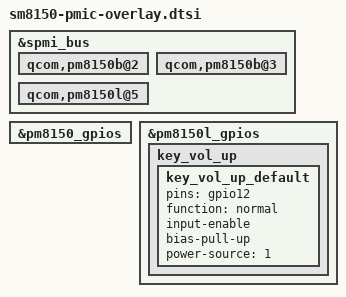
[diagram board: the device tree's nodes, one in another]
/*
 * Copyright (c) 2017-2018, The Linux Foundation. All rights reserved.
 *
 * This program is free software; you can redistribute it and/or modify
 * it under the terms of the GNU General Public License version 2 and
 * only version 2 as published by the Free Software Foundation.
 *
 * This program is distributed in the hope that it will be useful,
 * but WITHOUT ANY WARRANTY; without even the implied warranty of
 * MERCHANTABILITY or FITNESS FOR A PARTICULAR PURPOSE.  See the
 * GNU General Public License for more details.
 */

#include "pm8150.dtsi"
#include "pm8150l.dtsi"
#include <dt-bindings/pinctrl/qcom,pmic-gpio.h>

&spmi_bus {
	qcom,pm8150b@2 {
		/delete-node/qcom,usb-pdphy@1700;
		/delete-node/qcom,temp-alarm@2400;
	};
	qcom,pm8150b@3 {
		/delete-node/qcom,haptic@c000;
		/delete-node/qcom,leds@d400;
	};
	qcom,pm8150l@5 {
		/delete-node/qcom,lcdb@ec00;
		/delete-node/qcom,leds@d300;
		/delete-node/qcom,wled@d800;
		/delete-node/qcom,pwms@b100;
		/delete-node/qcom,leds@d000;
	};
};

/* PMIC GPIO pin control configurations: */
&pm8150_gpios {
};

&pm8150l_gpios {
	key_vol_up {
		key_vol_up_default: key_vol_up_default {
			pins = "gpio12";
			function = "normal";
			input-enable;
			bias-pull-up;
			power-source = <1>;
		};
	};
};
